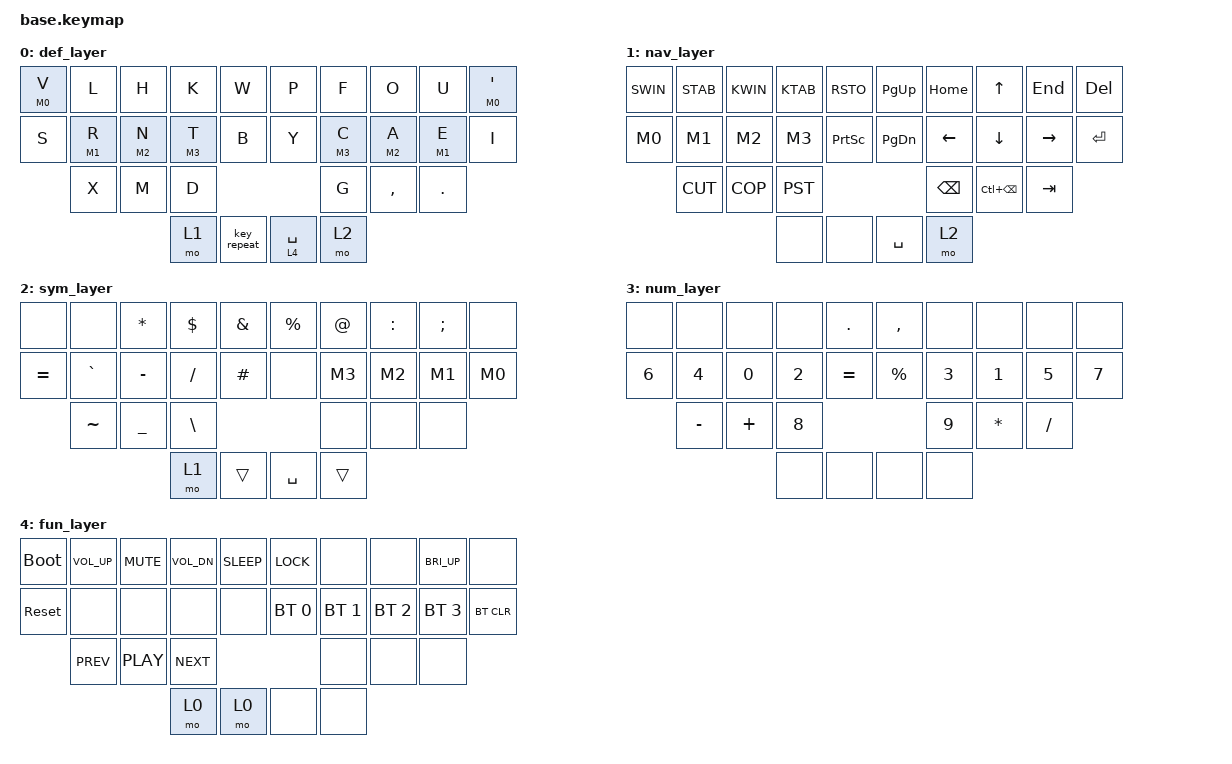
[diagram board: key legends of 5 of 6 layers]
#include <behaviors.dtsi>
#include <dt-bindings/zmk/bt.h>
#define ZMK_POINTING_DEFAULT_MOVE_VAL 1500  // default: 600
#define ZMK_POINTING_DEFAULT_SCRL_VAL 20    // default: 10
#include <dt-bindings/zmk/pointing.h>
#include "mouse.dtsi"

/* Layers */
#define DEF 0
#define NAV 1
#define SYM 2
#define NUM 3
#define FUN 4
#define MOU 5

/* Mod Sequence (Outer to Inner) */
#define M0 LGUI
#define M1 LALT
#define M2 LCTRL
#define M3 LSHFT

/* Shortcuts */
#define CUT LC(X)
#define COP LC(C)
#define PST LC(V)
#define UNDO LC(Z)
#define ALL LC(A)
#define TOP LC(HOME)
#define BOTTOM LC(END)
#define SWIN LA(TAB)
#define STAB LC(TAB)
#define KWIN LA(F4)
#define KTAB LC(W)
#define RSTO LC(LS(T))

/* More keys */
#define REP &key_repeat

/ {
    behaviors {
        home: home_ignoring_ctrl {
            compatible = "zmk,behavior-mod-morph";
            #binding-cells = <0>;
            bindings = <&kp HOME>, <&kp HOME>;
            mods = <(MOD_LCTL|MOD_RCTL)>;
        };
        end: end_ignoring_ctrl {
            compatible = "zmk,behavior-mod-morph";
            #binding-cells = <0>;
            bindings = <&kp END>, <&kp END>;
            mods = <(MOD_LCTL|MOD_RCTL)>;
        };
        bspc: backspace_delete {
            compatible = "zmk,behavior-mod-morph";
            #binding-cells = <0>;
            bindings = <&kp BSPC>, <&kp DEL>;
            mods = <(MOD_LSFT|MOD_RSFT)>;
        };
        plus: plus_zoom {
            compatible = "zmk,behavior-mod-morph";
            #binding-cells = <0>;
            bindings = <&kp PLUS>, <&kp LC(EQUAL)>;
            mods = <(MOD_LCTL|MOD_RCTL)>;
        };
    };

    conditional_layers {
        compatible = "zmk,conditional-layers";
        tri_layer {
            if-layers = <NAV SYM>;
            then-layer = <NUM>;
        };
    };

    combos {
        compatible = "zmk,combos";

        /*                 Key Positions
             0   1   2   3   4      5   6   7   8   9
            10  11  12  13  14     15  16  17  18  19
                20  21  22             23  24  25
                        26  27     28  29              */

        j { key-positions = <1 2>; bindings = <&kp J>; layers = <DEF>; };
        q { key-positions = <2 3>; bindings = <&kp Q>; layers = <DEF>; };
        z { key-positions = <20 21>; bindings = <&kp Z>; layers = <DEF>; };

        caps { key-positions = <1 8>; bindings = <&kp CAPS>; layers = <DEF>; };
        word { key-positions = <2 7>; bindings = <&caps_word>; layers = <DEF>; };


        lpar { key-positions = <3 13>; bindings = <&kp LPAR>; layers = <DEF SYM NUM>; };
        rpar { key-positions = <6 16>; bindings = <&kp RPAR>; layers = <DEF SYM NUM>; };
        lbrc { key-positions = <2 12>; bindings = <&kp LBRC>; layers = <DEF SYM NUM>; };
        rbrc { key-positions = <7 17>; bindings = <&kp RBRC>; layers = <DEF SYM NUM>; };
        lbkt { key-positions = <1 11>; bindings = <&kp LBKT>; layers = <DEF SYM NUM>; };
        rbkt { key-positions = <8 18>; bindings = <&kp RBKT>; layers = <DEF SYM NUM>; };
    };

    keymap {
        compatible = "zmk,keymap";

        def_layer {
            bindings = <
                &mt M0 V  &kp L     &kp H     &kp K     &kp W     &kp P     &kp F     &kp O     &kp U     &mt M0 SQT
                &kp S     &mt M1 R  &mt M2 N  &mt M3 T  &kp B     &kp Y     &mt M3 C  &mt M2 A  &mt M1 E  &kp I
                          &kp X     &kp M     &kp D   				        &kp G     &kp COMMA &kp DOT
                                           &mo 1	    REP       &lt 4 SPACE &mo 2
            >;
        };

        nav_layer {
            bindings = <
                &kp SWIN  &kp STAB  &kp KWIN  &kp KTAB  &kp RSTO  &kp PG_UP &kp HOME  &kp UP    &kp END  &kp DEL
                &kp M0    &kp M1    &kp M2    &kp M3    &kp PSCRN &kp PG_DN &kp LEFT  &kp DOWN  &kp RIGHT &kp RET
                          &kp CUT   &kp COP   &kp PST                       &kp BSPC  &kp LC(BSPC) &kp TAB
                                              &none     &none     &kp SPACE &mo 2
            >;  
        };

        sym_layer {
            bindings = < 
                &none     &none     &kp STAR  &kp DLLR  &kp AMPS  &kp PRCNT &kp AT    &kp COLON &kp SEMI  &none   
                &kp EQUAL &kp GRAVE &kp MINUS &kp FSLH  &kp HASH  &none     &kp M3    &kp M2    &kp M1    &kp M0
                          &kp TILDE &kp UNDER &kp BSLH                      &none     &none     &none
                                              &mo 1     &trans    &kp SPACE &trans
            >;  

        };

        num_layer {
            bindings = <
                &none     &none     &none     &none     &kp DOT   &kp COMMA &none     &none     &none     &none   
                &kp N6    &kp N4    &kp N0    &kp N2    &kp EQUAL &kp PRCNT &kp N3    &kp N1    &kp N5    &kp N7
                          &kp MINUS &kp PLUS  &kp N8                        &kp N9    &kp STAR  &kp SLASH
                                              &none     &none     &none     &none
            >;  
        };    

        fun_layer {
            bindings = <
                &bootloader &kp C_VOL_UP &kp C_MUTE &kp C_VOL_DN &kp C_SLEEP &kp K_LOCK &none     &none  &kp C_BRI_UP    &none
                &sys_reset  &none  &none    &none   &none  &bt BT_SEL 0 &bt BT_SEL 1 &bt BT_SEL 2 &bt BT_SEL 3 &bt BT_CLR
                            &kp C_PREV   &kp C_PLAY &kp C_NEXT       &none  &none    &none
                                &mo 0     &mo 0  &none    &none
            >;
        };              
        mouse_layer {
            bindings = <    
                &none   &none   &none   &none   &none   &kp PG_UP   U_MS_U   &kp PG_UP   &none   
                &none   &none   &none   &none   &none   U_WH_L   U_MS_L   U_MS_D   U_MS_R   U_WH_R
                        &none   &none   &none              &mkp MB1   &mkp MB2   &mkp MB3      
                            &none   &none   U_WH_U  U_WH_D

            >;
        };
    };
};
